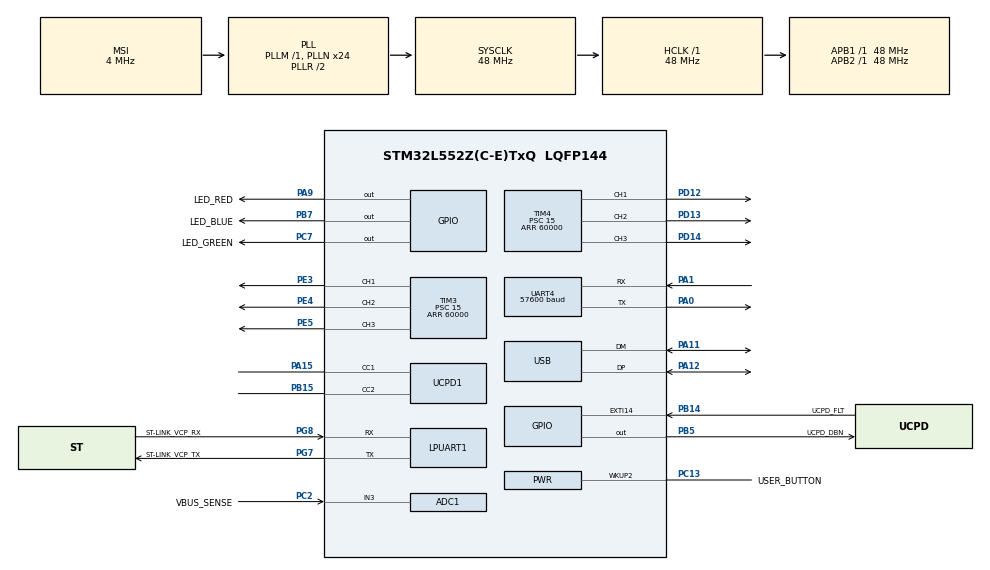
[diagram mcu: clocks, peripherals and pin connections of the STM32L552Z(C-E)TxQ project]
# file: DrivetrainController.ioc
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ADC1.Channel-0\#ChannelRegularConversion=ADC_CHANNEL_3
ADC1.NbrOfConversionFlag=1
ADC1.OffsetNumber-0\#ChannelRegularConversion=ADC_OFFSET_NONE
ADC1.Rank-0\#ChannelRegularConversion=1
ADC1.SamplingTime-0\#ChannelRegularConversion=ADC_SAMPLETIME_2CYCLES_5
ADC1.master=1
Dma.Request0=UART4_RX
Dma.UART4_RX.0.Channel_PRIV_NPRIV=DMA_CHANNEL_NPRIV_DISABLE
Dma.UART4_RX.0.Direction=DMA_PERIPH_TO_MEMORY
Dma.UART4_RX.0.EventEnable=DISABLE
Dma.UART4_RX.0.Instance=DMA1_Channel1
Dma.UART4_RX.0.MemDataAlignment=DMA_MDATAALIGN_BYTE
Dma.UART4_RX.0.MemInc=DMA_MINC_ENABLE
Dma.UART4_RX.0.Mode=DMA_NORMAL
Dma.UART4_RX.0.PeriphDataAlignment=DMA_PDATAALIGN_BYTE
Dma.UART4_RX.0.PeriphInc=DMA_PINC_DISABLE
Dma.UART4_RX.0.Polarity=HAL_DMAMUX_REQ_GEN_RISING
Dma.UART4_RX.0.Priority=DMA_PRIORITY_MEDIUM
Dma.UART4_RX.0.RequestNumber=1
Dma.UART4_RX.0.SignalID=NONE
Dma.UART4_RX.0.SyncEnable=DISABLE
Dma.UART4_RX.0.SyncPolarity=HAL_DMAMUX_SYNC_NO_EVENT
Dma.UART4_RX.0.SyncRequestNumber=1
Dma.UART4_RX.0.SyncSignalID=NONE
IWDG.Prescaler=IWDG_PRESCALER_128
IWDG.Reload=750
IWDG.Window=750
Mcu.Family=STM32L5
Mcu.Name=STM32L552Z(C-E)TxQ
Mcu.Package=LQFP144
Mcu.TrustZone=disable
NVIC.DMA1_Channel1_IRQn=true\:0\:0\:false\:false\:true\:false\:true\:true
NVIC.PriorityGroup=NVIC_PRIORITYGROUP_3
NVIC.TIM3_IRQn=true\:0\:0\:false\:false\:true\:true\:true\:true
NVIC.TIM4_IRQn=true\:0\:0\:false\:false\:true\:true\:true\:true
NVIC.UART4_IRQn=true\:0\:0\:false\:false\:true\:true\:true\:true
PA0.Mode=Asynchronous
PA0.Signal=UART4_TX
PA1.Mode=Asynchronous
PA1.Signal=UART4_RX
PA11.Mode=Device
PA11.Signal=USB_DM
PA12.Mode=Device
PA12.Signal=USB_DP
PA13\ (JTMS/SWDIO).Mode=Trace_Asynchronous_SW
PA13\ (JTMS/SWDIO).Signal=DEBUG_JTMS-SWDIO
PA14\ (JTCK/SWCLK).Mode=Trace_Asynchronous_SW
PA14\ (JTCK/SWCLK).Signal=DEBUG_JTCK-SWCLK
PA15\ (JTDI).Mode=Source_AllSignals
PA15\ (JTDI).Signal=UCPD1_CC1
PA9.GPIO_Label=LED_RED
PA9.Signal=GPIO_Output
PB14.GPIO_Label=UCPD_FLT
PB14.Signal=GPXTI14
PB15.Mode=Source_AllSignals
PB15.Signal=UCPD1_CC2
PB3\ (JTDO/TRACESWO).Mode=Trace_Asynchronous_SW
PB3\ (JTDO/TRACESWO).Signal=DEBUG_JTDO-SWO
PB5.GPIO_Label=UCPD_DBN
PB5.Signal=GPIO_Output
PB7.GPIO_Label=LED_BLUE
PB7.Signal=GPIO_Output
PC13.GPIO_Label=USER_BUTTON
PC13.Mode=WakeUp1
PC13.Signal=PWR_WKUP2
PC14-OSC32_IN\ (PC14).Mode=LSE-External-Oscillator
PC14-OSC32_IN\ (PC14).Signal=RCC_OSC32_IN
PC15-OSC32_OUT\ (PC15).Mode=LSE-External-Oscillator
PC15-OSC32_OUT\ (PC15).Signal=RCC_OSC32_OUT
PC2.GPIO_Label=VBUS_SENSE
PC2.Signal=ADCx_IN3
PC7.GPIO_Label=LED_GREEN
PC7.Signal=GPIO_Output
PD12.Signal=S_TIM4_CH1
PD13.Signal=S_TIM4_CH2
PD14.Signal=S_TIM4_CH3
PE3.Signal=S_TIM3_CH1
PE4.Signal=S_TIM3_CH2
PE5.Signal=S_TIM3_CH3
PG7.GPIO_Label=ST-LINK_VCP_TX
PG7.Mode=Asynchronous
PG7.Signal=LPUART1_TX
PG8.GPIO_Label=ST-LINK_VCP_RX
PG8.Mode=Asynchronous
PG8.Signal=LPUART1_RX
ProjectManager.HeapSize=0x200
ProjectManager.StackSize=0x400
ProjectManager.TargetToolchain=STM32CubeIDE
RCC.ADCCLockSelection=RCC_ADCCLKSOURCE_SYSCLK
RCC.ADCFreq_Value=48000000
RCC.AHBFreq_Value=48000000
RCC.APB1Freq_Value=48000000
RCC.APB1TimFreq_Value=48000000
RCC.APB2Freq_Value=48000000
RCC.APB2TimFreq_Value=48000000
RCC.CK48CLockSelection=RCC_USBCLKSOURCE_HSI48
RCC.CortexFreq_Value=48000000
RCC.HCLKFreq_Value=48000000
RCC.HSE_VALUE=8000000
RCC.HSI48_VALUE=48000000
RCC.HSI_VALUE=16000000
RCC.MSI_VALUE=4000000
RCC.PLLN=24
RCC.PLLSAI1N=24
RCC.RTCClockSelection=RCC_RTCCLKSOURCE_LSE
RCC.SYSCLKFreq_VALUE=48000000
RCC.SYSCLKSource=RCC_SYSCLKSOURCE_PLLCLK
RCC.USBFreq_Value=48000000
RCC.VCOOutputFreq_Value=96000000
SH.ADCx_IN3.0=ADC1_IN3,IN3-Single-Ended
SH.S_TIM3_CH1.0=TIM3_CH1,PWM Generation1 CH1
SH.S_TIM3_CH2.0=TIM3_CH2,PWM Generation2 CH2
SH.S_TIM3_CH3.0=TIM3_CH3,PWM Generation3 CH3
SH.S_TIM4_CH1.0=TIM4_CH1,PWM Generation1 CH1
SH.S_TIM4_CH2.0=TIM4_CH2,PWM Generation2 CH2
SH.S_TIM4_CH3.0=TIM4_CH3,PWM Generation3 CH3
TIM3.AutoReloadPreload=TIM_AUTORELOAD_PRELOAD_ENABLE
TIM3.Channel-PWM\ Generation1\ CH1=TIM_CHANNEL_1
TIM3.Channel-PWM\ Generation2\ CH2=TIM_CHANNEL_2
TIM3.Channel-PWM\ Generation3\ CH3=TIM_CHANNEL_3
TIM3.Period=60000
TIM3.Prescaler=15
TIM3.Pulse-PWM\ Generation1\ CH1=4500
TIM4.AutoReloadPreload=TIM_AUTORELOAD_PRELOAD_ENABLE
TIM4.Channel-PWM\ Generation1\ CH1=TIM_CHANNEL_1
TIM4.Channel-PWM\ Generation2\ CH2=TIM_CHANNEL_2
TIM4.Channel-PWM\ Generation3\ CH3=TIM_CHANNEL_3
TIM4.Period=60000
TIM4.Prescaler=15
UART4.BaudRate=57600
VP_ICACHE_VS_ICACHE.Mode=DirectMappedCache
VP_IWDG_VS_IWDG.Mode=IWDG_Activate
VP_PWR_VS_DBSignals.Mode=DisableDeadBatterySignals
VP_RTC_VS_RTC_Activate.Mode=RTC_Enabled
VP_TIM3_VS_ClockSourceINT.Mode=Internal
VP_TIM4_VS_ClockSourceINT.Mode=Internal
board=NUCLEO-L552ZE-Q

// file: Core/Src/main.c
/* USER CODE BEGIN Header */
/**
  ******************************************************************************
  * @file           : main.c
  * @brief          : Main program body
  ******************************************************************************
  * @attention
  *
  * Copyright (c) 2024 STMicroelectronics.
  * All rights reserved.
  *
  * This software is licensed under terms that can be found in the LICENSE file
  * in the root directory of this software component.
  * If no LICENSE file comes with this software, it is provided AS-IS.
  *
  ******************************************************************************
  */
/* USER CODE END Header */
#include "main.h"
#include "adc.h"
#include "dma.h"
#include "icache.h"
#include "iwdg.h"
#include "usart.h"
#include "rtc.h"
#include "tim.h"
#include "ucpd.h"
#include "usb.h"
#include "gpio.h"

void SystemClock_Config(void);

int main(void)
{

  /* MCU Configuration--------------------------------------------------------*/

  /* Reset of all peripherals, Initializes the Flash interface and the Systick. */
  HAL_Init();

  /* Configure the system clock */
  SystemClock_Config();

  /* Initialize all configured peripherals */
  MX_GPIO_Init();
  MX_DMA_Init();
  MX_LPUART1_UART_Init();
  MX_RTC_Init();
  MX_UCPD1_Init();
  MX_USB_PCD_Init();
  MX_ADC1_Init();
  MX_TIM3_Init();
  MX_TIM4_Init();
  MX_UART4_Init();
  MX_ICACHE_Init();
  MX_IWDG_Init();
  /* USER CODE BEGIN 2 */
  //UartHandshake();
  MotorPwmInterfaceInit();
  UartHandshake();
  /* USER CODE END 2 */

  /* Infinite loop */
  while (1)
  {

  }
}

void SystemClock_Config(void)
{
  RCC_OscInitTypeDef RCC_OscInitStruct = {0};
  RCC_ClkInitTypeDef RCC_ClkInitStruct = {0};

  /** Configure the main internal regulator output voltage
  */
  if (HAL_PWREx_ControlVoltageScaling(PWR_REGULATOR_VOLTAGE_SCALE1) != HAL_OK)
  {
    Error_Handler();
  }

  /** Configure LSE Drive Capability
  */
  HAL_PWR_EnableBkUpAccess();
  __HAL_RCC_LSEDRIVE_CONFIG(RCC_LSEDRIVE_LOW);

  /** Initializes the RCC Oscillators according to the specified parameters
  * in the RCC_OscInitTypeDef structure.
  */
  RCC_OscInitStruct.OscillatorType = RCC_OSCILLATORTYPE_HSI48|RCC_OSCILLATORTYPE_LSI
                              |RCC_OSCILLATORTYPE_LSE|RCC_OSCILLATORTYPE_MSI;
  RCC_OscInitStruct.LSEState = RCC_LSE_ON;
  RCC_OscInitStruct.HSI48State = RCC_HSI48_ON;
  RCC_OscInitStruct.LSIDiv = RCC_LSI_DIV1;
  RCC_OscInitStruct.LSIState = RCC_LSI_ON;
  RCC_OscInitStruct.MSIState = RCC_MSI_ON;
  RCC_OscInitStruct.MSICalibrationValue = RCC_MSICALIBRATION_DEFAULT;
  RCC_OscInitStruct.MSIClockRange = RCC_MSIRANGE_6;
  RCC_OscInitStruct.PLL.PLLState = RCC_PLL_ON;
  RCC_OscInitStruct.PLL.PLLSource = RCC_PLLSOURCE_MSI;
  RCC_OscInitStruct.PLL.PLLM = 1;
  RCC_OscInitStruct.PLL.PLLN = 24;
  RCC_OscInitStruct.PLL.PLLP = RCC_PLLP_DIV7;
  RCC_OscInitStruct.PLL.PLLQ = RCC_PLLQ_DIV2;
  RCC_OscInitStruct.PLL.PLLR = RCC_PLLR_DIV2;
  if (HAL_RCC_OscConfig(&RCC_OscInitStruct) != HAL_OK)
  {
    Error_Handler();
  }

  /** Initializes the CPU, AHB and APB buses clocks
  */
  RCC_ClkInitStruct.ClockType = RCC_CLOCKTYPE_HCLK|RCC_CLOCKTYPE_SYSCLK
                              |RCC_CLOCKTYPE_PCLK1|RCC_CLOCKTYPE_PCLK2;
  RCC_ClkInitStruct.SYSCLKSource = RCC_SYSCLKSOURCE_PLLCLK;
  RCC_ClkInitStruct.AHBCLKDivider = RCC_SYSCLK_DIV1;
  RCC_ClkInitStruct.APB1CLKDivider = RCC_HCLK_DIV1;
  RCC_ClkInitStruct.APB2CLKDivider = RCC_HCLK_DIV1;

  if (HAL_RCC_ClockConfig(&RCC_ClkInitStruct, FLASH_LATENCY_2) != HAL_OK)
  {
    Error_Handler();
  }
}

void Error_Handler(void)
{
  __disable_irq();
  while (1)
  {
  }
}
